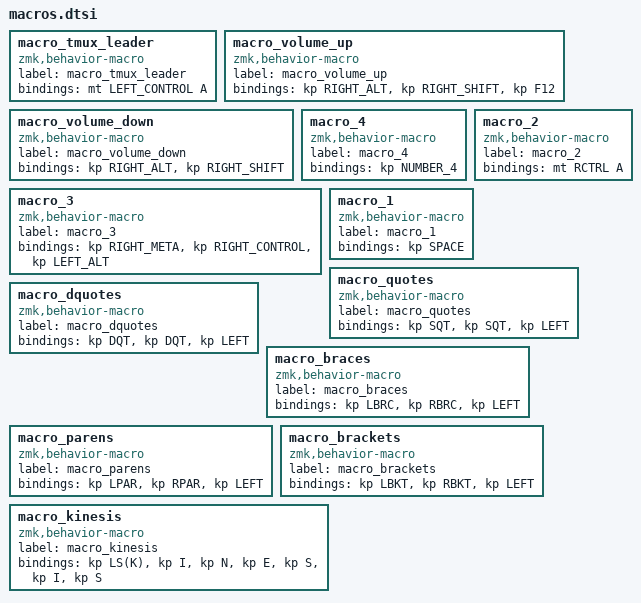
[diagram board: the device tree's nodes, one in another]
macro_tmux_leader: macro_tmux_leader{
compatible = "zmk,behavior-macro";
label = "macro_tmux_leader";
#binding-cells = <0>;
bindings = <&mt LEFT_CONTROL A>;
};
macro_volume_up: macro_volume_up{
compatible = "zmk,behavior-macro";
label = "macro_volume_up";
#binding-cells = <0>;
bindings = <&kp RIGHT_ALT>, <&kp RIGHT_SHIFT>, <&kp F12>;
};
macro_volume_down: macro_volume_down{
compatible = "zmk,behavior-macro";
label = "macro_volume_down";
#binding-cells = <0>;
bindings = <&kp RIGHT_ALT>, <&kp RIGHT_SHIFT>;
};
macro_4: macro_4{
compatible = "zmk,behavior-macro";
label = "macro_4";
#binding-cells = <0>;
bindings = <&kp NUMBER_4>;
};
macro_3: macro_3{
compatible = "zmk,behavior-macro";
label = "macro_3";
#binding-cells = <0>;
bindings = <&kp RIGHT_META>, <&kp RIGHT_CONTROL>, <&kp LEFT_ALT>;
};
macro_2: macro_2{
compatible = "zmk,behavior-macro";
label = "macro_2";
#binding-cells = <0>;
bindings = <&mt RCTRL A>;
};
macro_1: macro_1{
compatible = "zmk,behavior-macro";
label = "macro_1";
#binding-cells = <0>;
bindings = <&kp SPACE>;
};
macro_quotes: macro_quotes{
compatible = "zmk,behavior-macro";
label = "macro_quotes";
#binding-cells = <0>;
bindings = <&kp SQT>, <&kp SQT>, <&kp LEFT>;
};
macro_dquotes: macro_dquotes{
compatible = "zmk,behavior-macro";
label = "macro_dquotes";
#binding-cells = <0>;
bindings = <&kp DQT>, <&kp DQT>, <&kp LEFT>;
};
macro_braces: macro_braces{
compatible = "zmk,behavior-macro";
label = "macro_braces";
#binding-cells = <0>;
bindings = <&kp LBRC>, <&kp RBRC>, <&kp LEFT>;
};
macro_parens: macro_parens{
compatible = "zmk,behavior-macro";
label = "macro_parens";
#binding-cells = <0>;
bindings = <&kp LPAR>, <&kp RPAR>, <&kp LEFT>;
};
macro_brackets: macro_brackets{
compatible = "zmk,behavior-macro";
label = "macro_brackets";
#binding-cells = <0>;
bindings = <&kp LBKT>, <&kp RBKT>, <&kp LEFT>;
};
macro_kinesis: macro_kinesis{
compatible = "zmk,behavior-macro";
label = "macro_kinesis";
#binding-cells = <0>;
bindings = <&kp LS(K)>, <&kp I>, <&kp N>, <&kp E>, <&kp S>, <&kp I>, <&kp S>;
};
